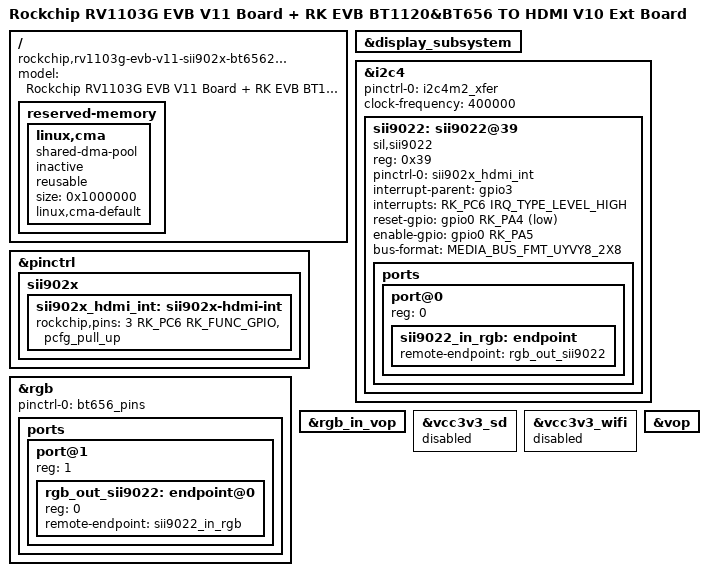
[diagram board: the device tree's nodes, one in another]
// SPDX-License-Identifier: (GPL-2.0+ OR MIT)
/*
 * Copyright (c) 2022 Rockchip Electronics Co., Ltd.
 */

/dts-v1/;

#include "rv1103g-evb-v11.dts"
#include <dt-bindings/display/media-bus-format.h>

/ {
	model = "Rockchip RV1103G EVB V11 Board + RK EVB BT1120&BT656 TO HDMI V10 Ext Board";
	compatible = "rockchip,rv1103g-evb-v11-sii902x-bt6562hdmi", "rockchip,rv1103";

	reserved-memory {
		#address-cells = <1>;
		#size-cells = <1>;
		ranges;

		linux,cma {
			compatible = "shared-dma-pool";
			inactive;
			reusable;
			size = <0x1000000>;
			linux,cma-default;
		};
	};
};

&display_subsystem {
	status = "okay";
};

&i2c4 {
	pinctrl-names = "default";
	pinctrl-0 = <&i2c4m2_xfer>;
	clock-frequency = <400000>;
	status = "okay";

	sii9022: sii9022@39 {
		compatible = "sil,sii9022";
		reg = <0x39>;
		pinctrl-names = "default";
		pinctrl-0 = <&sii902x_hdmi_int>;
		interrupt-parent = <&gpio3>;
		interrupts = <RK_PC6 IRQ_TYPE_LEVEL_HIGH>;
		reset-gpio = <&gpio0 RK_PA4 GPIO_ACTIVE_LOW>;
		enable-gpio = <&gpio0 RK_PA5 GPIO_ACTIVE_HIGH>;
		bus-format = <MEDIA_BUS_FMT_UYVY8_2X8>;

		ports {
			#address-cells = <1>;
			#size-cells = <0>;

			port@0 {
				reg = <0>;

				sii9022_in_rgb: endpoint {
					remote-endpoint = <&rgb_out_sii9022>;
				};
			};
		};
	};
};

&pinctrl {
	sii902x {
		sii902x_hdmi_int: sii902x-hdmi-int {
			rockchip,pins = <3 RK_PC6 RK_FUNC_GPIO &pcfg_pull_up>;
		};
	};
};

&rgb {
	status = "okay";
	pinctrl-names = "default";
	pinctrl-0 = <&bt656_pins>;

	ports {
		port@1 {
			reg = <1>;
			#address-cells = <1>;
			#size-cells = <0>;

			rgb_out_sii9022: endpoint@0 {
				reg = <0>;
				remote-endpoint = <&sii9022_in_rgb>;
			};
		};
	};
};

&rgb_in_vop {
	status = "okay";
};

/*
 * The pins of vcc3v3_sd/vcc3v3_wifi and lcd are multiplexed
 */
&vcc3v3_sd {
	status = "disabled";
};

&vcc3v3_wifi {
	status = "disabled";
};

&vop {
	status = "okay";
};
